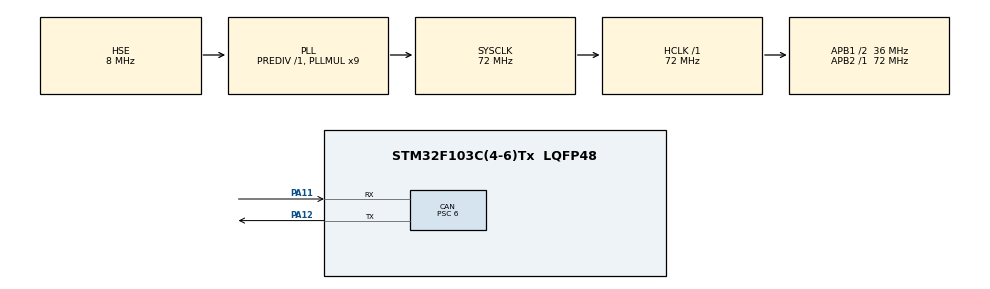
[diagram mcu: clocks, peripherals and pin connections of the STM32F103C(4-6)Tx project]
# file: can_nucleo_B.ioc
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CAN.BS1=CAN_BS1_9TQ
CAN.BS2=CAN_BS2_2TQ
CAN.CalculateBaudRate=499999
CAN.CalculateTimeBit=2000
CAN.CalculateTimeQuantum=166.66666666666669
CAN.Prescaler=6
Mcu.Family=STM32F1
Mcu.Name=STM32F103C(4-6)Tx
Mcu.Package=LQFP48
NVIC.PriorityGroup=NVIC_PRIORITYGROUP_4
PA11.Mode=CAN_Activate
PA11.Signal=CAN_RX
PA12.Mode=CAN_Activate
PA12.Signal=CAN_TX
PD0-OSC_IN.Mode=HSE-External-Oscillator
PD0-OSC_IN.Signal=RCC_OSC_IN
PD1-OSC_OUT.Mode=HSE-External-Oscillator
PD1-OSC_OUT.Signal=RCC_OSC_OUT
ProjectManager.HeapSize=0x200
ProjectManager.StackSize=0x400
ProjectManager.TargetToolchain=STM32CubeIDE
RCC.AHBFreq_Value=72000000
RCC.APB1CLKDivider=RCC_HCLK_DIV2
RCC.APB1Freq_Value=36000000
RCC.APB1TimFreq_Value=72000000
RCC.APB2Freq_Value=72000000
RCC.APB2TimFreq_Value=72000000
RCC.HCLKFreq_Value=72000000
RCC.PLLMUL=RCC_PLL_MUL9
RCC.PLLSourceVirtual=RCC_PLLSOURCE_HSE
RCC.SYSCLKFreq_VALUE=72000000
RCC.SYSCLKSource=RCC_SYSCLKSOURCE_PLLCLK
RCC.USBFreq_Value=72000000
VP_SYS_VS_ND.Mode=No_Debug
board=custom

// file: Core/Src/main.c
/* USER CODE BEGIN Header */
/**
  ******************************************************************************
  * @file           : main.c
  * @brief          : Main program body
  ******************************************************************************
  * @attention
  *
  * Copyright (c) 2025 STMicroelectronics.
  * All rights reserved.
  *
  * This software is licensed under terms that can be found in the LICENSE file
  * in the root directory of this software component.
  * If no LICENSE file comes with this software, it is provided AS-IS.
  *
  ******************************************************************************
  */
/* USER CODE END Header */
#include "main.h"

/* USER CODE BEGIN Includes */
#include <string.h>
#include <stdbool.h>
/* USER CODE END Includes */

CAN_HandleTypeDef hcan;

CAN_TxHeaderTypeDef B_TxHeader;
uint32_t B_TxMailbox;
uint8_t  B_TxData[8];

uint32_t env_tick = 0;
uint32_t hb_tick  = 0;

// Фейкові ENV дані
int16_t  temp_c_x100 = 2300;   // 23.00 °C
uint16_t press_x10   = 10130;  // 1013.0 hPa
uint8_t  rh_x2       = 80;     // 40% (80/2)
uint16_t lux         = 100;    // 100 lux

void SystemClock_Config(void);
static void MX_GPIO_Init(void);
static void MX_CAN_Init(void);

/* USER CODE BEGIN 0 */

uint8_t crc8(const uint8_t *data, uint8_t len)
{
    uint8_t crc = 0x00;
    const uint8_t poly = 0x07; // x^8 + x^2 + x + 1

    for (uint8_t i = 0; i < len; i++)
    {
        crc ^= data[i];
        for (uint8_t b = 0; b < 8; b++)
        {
            if (crc & 0x80)
                crc = (crc << 1) ^ poly;
            else
                crc <<= 1;
        }
    }
    return crc;
}

// 0x180 TLM_slow: T(Q9.7) | P(Q13.3) | RH(%*2) | lux(16b)
void B_Send_TLM180(void)
{
    B_TxHeader.StdId = 0x180;
    B_TxHeader.ExtId = 0;
    B_TxHeader.IDE   = CAN_ID_STD;
    B_TxHeader.RTR   = CAN_RTR_DATA;
    B_TxHeader.DLC   = 8;
    B_TxHeader.TransmitGlobalTime = DISABLE;

    temp_c_x100 += 5;  // +0.05°C
    if (temp_c_x100 > 2800) temp_c_x100 = 2300;

    press_x10 += 1;
    if (press_x10 > 10180) press_x10 = 10130;

    rh_x2 += 1;       // +0.5%
    if (rh_x2 > 160) rh_x2 = 80;  // 40..80%

    lux += 20;
    if (lux > 1000) lux = 100;

    B_TxData[0] = (uint8_t)(temp_c_x100 >> 8);
    B_TxData[1] = (uint8_t)(temp_c_x100 & 0xFF);

    B_TxData[2] = (uint8_t)(press_x10 >> 8);
    B_TxData[3] = (uint8_t)(press_x10 & 0xFF);

    B_TxData[4] = rh_x2;

    B_TxData[5] = (uint8_t)(lux >> 8);
    B_TxData[6] = (uint8_t)(lux & 0xFF);

    B_TxData[7] = 0x00;

    HAL_CAN_AddTxMessage(&hcan, &B_TxHeader, B_TxData, &B_TxMailbox);
}

// HB B: 0x082
void B_Send_HB082(void)
{
    B_TxHeader.StdId = 0x082;
    B_TxHeader.ExtId = 0;
    B_TxHeader.IDE   = CAN_ID_STD;
    B_TxHeader.RTR   = CAN_RTR_DATA;
    B_TxHeader.DLC   = 1;
    B_TxHeader.TransmitGlobalTime = DISABLE;

    B_TxData[0] = 0xB2; // статус B

    HAL_CAN_AddTxMessage(&hcan, &B_TxHeader, B_TxData, &B_TxMailbox);
}
/* USER CODE END 0 */

int main(void)
{

  /* MCU Configuration--------------------------------------------------------*/

  /* Reset of all peripherals, Initializes the Flash interface and the Systick. */
  HAL_Init();

  /* Configure the system clock */
  SystemClock_Config();

  /* Initialize all configured peripherals */
  MX_GPIO_Init();
  MX_CAN_Init();
  /* USER CODE BEGIN 2 */
  HAL_CAN_Start(&hcan);

  /* USER CODE END 2 */

  /* Infinite loop */
  while (1)
  {

    /* USER CODE BEGIN 3 */
	  uint32_t now = HAL_GetTick();

	  if (now - env_tick >= 1000)
	  {
		  env_tick = now;
		  B_Send_TLM180();
	  }

	  if (now - hb_tick >= 1000)
	  {
		  hb_tick = now;
		  B_Send_HB082();
	  }
  }
  /* USER CODE END 3 */
}

void SystemClock_Config(void)
{
  RCC_OscInitTypeDef RCC_OscInitStruct = {0};
  RCC_ClkInitTypeDef RCC_ClkInitStruct = {0};

  /** Initializes the RCC Oscillators according to the specified parameters
  * in the RCC_OscInitTypeDef structure.
  */
  RCC_OscInitStruct.OscillatorType = RCC_OSCILLATORTYPE_HSE;
  RCC_OscInitStruct.HSEState = RCC_HSE_ON;
  RCC_OscInitStruct.HSEPredivValue = RCC_HSE_PREDIV_DIV1;
  RCC_OscInitStruct.HSIState = RCC_HSI_ON;
  RCC_OscInitStruct.PLL.PLLState = RCC_PLL_ON;
  RCC_OscInitStruct.PLL.PLLSource = RCC_PLLSOURCE_HSE;
  RCC_OscInitStruct.PLL.PLLMUL = RCC_PLL_MUL9;
  if (HAL_RCC_OscConfig(&RCC_OscInitStruct) != HAL_OK)
  {
    Error_Handler();
  }

  /** Initializes the CPU, AHB and APB buses clocks
  */
  RCC_ClkInitStruct.ClockType = RCC_CLOCKTYPE_HCLK|RCC_CLOCKTYPE_SYSCLK
                              |RCC_CLOCKTYPE_PCLK1|RCC_CLOCKTYPE_PCLK2;
  RCC_ClkInitStruct.SYSCLKSource = RCC_SYSCLKSOURCE_PLLCLK;
  RCC_ClkInitStruct.AHBCLKDivider = RCC_SYSCLK_DIV1;
  RCC_ClkInitStruct.APB1CLKDivider = RCC_HCLK_DIV2;
  RCC_ClkInitStruct.APB2CLKDivider = RCC_HCLK_DIV1;

  if (HAL_RCC_ClockConfig(&RCC_ClkInitStruct, FLASH_LATENCY_2) != HAL_OK)
  {
    Error_Handler();
  }
}

static void MX_CAN_Init(void)
{

  hcan.Instance = CAN1;
  hcan.Init.Prescaler = 6;
  hcan.Init.Mode = CAN_MODE_NORMAL;
  hcan.Init.SyncJumpWidth = CAN_SJW_1TQ;
  hcan.Init.TimeSeg1 = CAN_BS1_9TQ;
  hcan.Init.TimeSeg2 = CAN_BS2_2TQ;
  hcan.Init.TimeTriggeredMode = DISABLE;
  hcan.Init.AutoBusOff = DISABLE;
  hcan.Init.AutoWakeUp = DISABLE;
  hcan.Init.AutoRetransmission = DISABLE;
  hcan.Init.ReceiveFifoLocked = DISABLE;
  hcan.Init.TransmitFifoPriority = DISABLE;
  if (HAL_CAN_Init(&hcan) != HAL_OK)
  {
    Error_Handler();
  }

}

static void MX_GPIO_Init(void)
{

  /* GPIO Ports Clock Enable */
  __HAL_RCC_GPIOD_CLK_ENABLE();
  __HAL_RCC_GPIOA_CLK_ENABLE();

}

void Error_Handler(void)
{
  __disable_irq();
  while (1)
  {
  }
}
